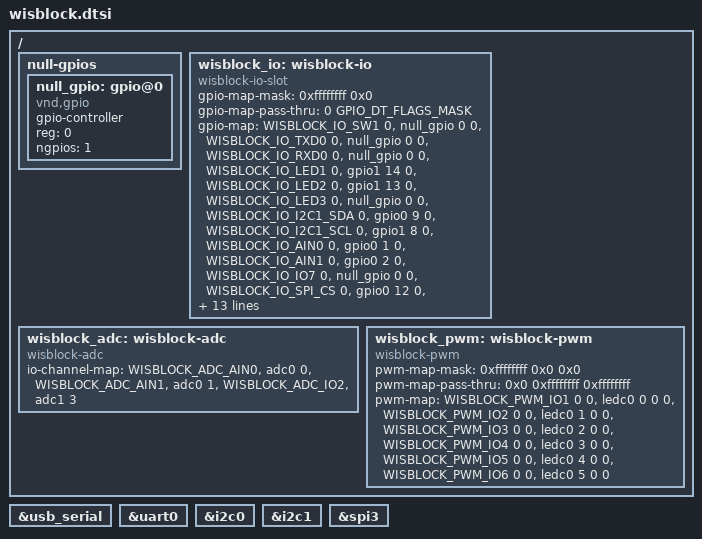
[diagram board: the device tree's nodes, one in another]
/*
 * SPDX-License-Identifier: Apache-2.0
 * Copyright (c) 2026 RAKwireless Technology Limited
 */

#include <zephyr/dt-bindings/gpio/wisblock-io-slot.h>
#include <zephyr/dt-bindings/adc/wisblock-adc.h>
#include <zephyr/dt-bindings/pwm/wisblock-pwm.h>

/ {
	null-gpios {
		#address-cells = <1>;
		#size-cells = <0>;

		null_gpio: gpio@0 {
			compatible = "vnd,gpio";
			gpio-controller;
			status = "okay";
			reg = <0>;
			#gpio-cells = <2>;
			ngpios = <1>;
		};
	};

	wisblock_io: wisblock-io {
		compatible = "wisblock-io-slot";
		#gpio-cells = <2>;
		gpio-map-mask = <0xffffffff 0x0>;
		gpio-map-pass-thru = <0 GPIO_DT_FLAGS_MASK>;

		/**
		 * Note:
		 * 	GPIO33, GPIO34, GPIO35, GPIO36, GPIO37 is
		 * 	not available in extended memory mode, so they are not
		 * 	included in the gpio-map.
		 */
		gpio-map =
			<WISBLOCK_IO_SW1	0	&null_gpio	0	0>, /* Not connected */
			<WISBLOCK_IO_TXD0	0	&null_gpio	0	0>, /* Not connected */
			<WISBLOCK_IO_RXD0	0	&null_gpio	0	0>, /* Not connected */
			<WISBLOCK_IO_LED1	0	&gpio1	14	0>, /* GPIO44 */
			<WISBLOCK_IO_LED2	0	&gpio1	13	0>, /* GPIO43 */
			<WISBLOCK_IO_LED3	0	&null_gpio	0	0>, /* Not connected */
			<WISBLOCK_IO_I2C1_SDA	0	&gpio0	9	0>, /* GPIO9 */
			<WISBLOCK_IO_I2C1_SCL	0	&gpio1	8	0>, /* GPIO40 */
			<WISBLOCK_IO_AIN0	0	&gpio0	1	0>, /* GPIO1 */
			<WISBLOCK_IO_AIN1	0	&gpio0	2	0>, /* GPIO2 */
			<WISBLOCK_IO_IO7	0	&null_gpio	0	0>, /* Not connected */
			<WISBLOCK_IO_SPI_CS	0	&gpio0	12	0>, /* GPIO12 */
			<WISBLOCK_IO_SPI_CLK	0	&gpio0	13	0>, /* GPIO13 */
			<WISBLOCK_IO_SPI_MISO	0	&gpio0	10	0>, /* GPIO10 */
			<WISBLOCK_IO_SPI_MOSI	0	&gpio0	11	0>, /* GPIO11 */
			<WISBLOCK_IO_IO1	0	&gpio0	21	0>, /* GPIO21 */
			<WISBLOCK_IO_IO2	0	&gpio0	14	0>, /* GPIO14 */
			<WISBLOCK_IO_IO3	0	&gpio1	9	0>, /* GPIO41 */
			<WISBLOCK_IO_IO4	0	&gpio1	10	0>, /* GPIO42 */
			<WISBLOCK_IO_TXD1	0	&gpio1	11	0>, /* GPIO43 */
			<WISBLOCK_IO_RXD1	0	&gpio1	12	0>, /* GPIO44 */
			<WISBLOCK_IO_I2C2_SDA	0	&gpio0	17	0>, /* GPIO17 */
			<WISBLOCK_IO_I2C2_SCL	0	&gpio0	18	0>, /* GPIO18 */
			<WISBLOCK_IO_IO5	0	&gpio1	6	0>, /* GPIO38 */
			<WISBLOCK_IO_IO6	0	&gpio1	7	0>; /* GPIO39 */
	};

	wisblock_adc: wisblock-adc {
		compatible = "wisblock-adc";
		#io-channel-cells = <1>;
		io-channel-map =
			<WISBLOCK_ADC_AIN0	&adc0	0>,
			<WISBLOCK_ADC_AIN1	&adc0	1>,
			<WISBLOCK_ADC_IO2	&adc1	3>;
	};

	wisblock_pwm: wisblock-pwm {
		compatible = "wisblock-pwm";
		#pwm-cells = <3>;
		pwm-map-mask = <0xffffffff 0x0 0x0>;
		pwm-map-pass-thru = <0x0 0xffffffff 0xffffffff>;

		pwm-map =
			<WISBLOCK_PWM_IO1	0	0	&ledc0	0	0	0>,
			<WISBLOCK_PWM_IO2	0	0	&ledc0	1	0	0>,
			<WISBLOCK_PWM_IO3	0	0	&ledc0	2	0	0>,
			<WISBLOCK_PWM_IO4	0	0	&ledc0	3	0	0>,
			<WISBLOCK_PWM_IO5	0	0	&ledc0	4	0	0>,
			<WISBLOCK_PWM_IO6	0	0	&ledc0	5	0	0>;
	};
};

wisblock_console: &usb_serial {};

wisblock_uart1: &uart0 {};
wisblock_i2c1: &i2c0 {};
wisblock_i2c2: &i2c1 {};
wisblock_spi: &spi3 {};
